# R7KA8M2AD register map
Vendor: Renesas Electronics Corporation; Series: RA8; File version: 1.10.02
CPU: CM85 r0p2, little endian, MPU, FPU, VTOR, 4 interrupt priority bits, 96 interrupts
Registers are 32-bit, read-write, reset 0x0 unless marked. A register's access mark holds for its fields unless they carry their own. Offsets are from the block's base; [hi:lo] are bit positions; {n}, {i} and the like mark numbered series; 'fields as' and 'values as' point back to an identical list.

## MFWD (part 2 of 2) — Forwarding engine
Base 0x403C0000
Same registers: MFWD_NS 0x503C0000
{0x40A0+4i} FWLTHTL{i} (i=1..4) — L3 Table Learn Register {i}
  [31:0] LTHSLP{i} — L3 Stream Learn Part {i}
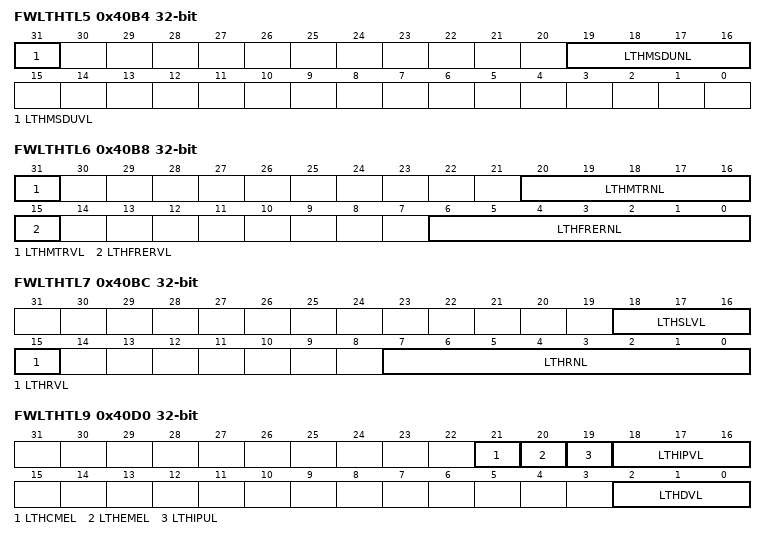
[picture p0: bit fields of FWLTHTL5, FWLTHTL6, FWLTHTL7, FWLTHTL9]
0x40B4 FWLTHTL5 — L3 Table Learn Register 5
  [31] LTHMSDUVL — L3 MSDU Valid Learn
  [19:16] LTHMSDUNL — L3 MSDU Number Learn
0x40B8 FWLTHTL6 — L3 Table Learn Register 6
  [31] LTHMTRVL — L3 Meter Valid Learn
  [20:16] LTHMTRNL — L3 Meter Number Learn
  [15] LTHFRERVL — L3 FRER Valid Learn
  [6:0] LTHFRERNL — L3 FRER Number Learn
0x40BC FWLTHTL7 — L3 Table Learn Register 7
  [18:16] LTHSLVL — L3 Source Lock Vector Learn
  [15] LTHRVL — L3 Routing Valid Learn
  [7:0] LTHRNL — L3 Routing Number Learn
0x40C0 FWLTHTL80 — L3 Table Learn Register 80
  [5:0] LTHCSDL — L3 CPU Sub-Destination Learn
0x40D0 FWLTHTL9 — L3 Table Learn Register 9
  [21] LTHCMEL — L3 CPU Mirroring Enable Learn
  [20] LTHEMEL — L3 Ethernet Mirroring Enable Learn
  [19] LTHIPUL — L3 Internal Priority Update Learn
  [18:16] LTHIPVL — L3 Internal Priority Value Learn
  [2:0] LTHDVL — L3 Destination Vector Learn
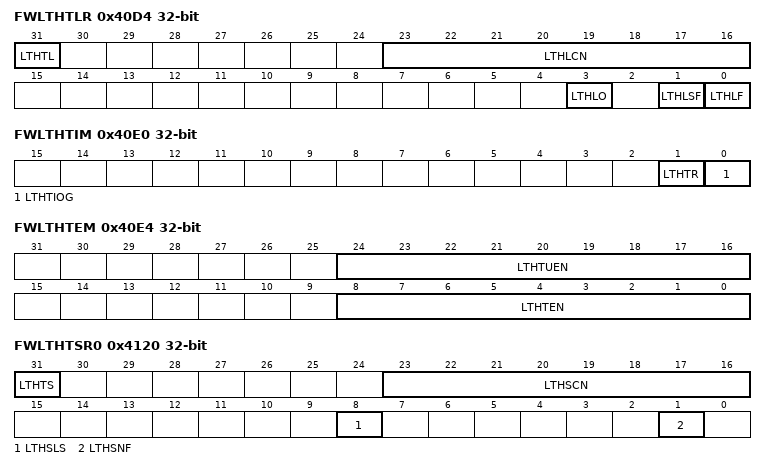
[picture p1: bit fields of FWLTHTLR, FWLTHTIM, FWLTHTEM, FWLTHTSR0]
0x40D4 FWLTHTLR ro — L3 Table Learn Result Register
  [31] LTHTL — L3 Table Learn
  [23:16] LTHLCN — L3 Learn Collision Number
  [3] LTHLO — L3 Learn Overwrite
    0=The entry learning did not overwrite an existing entry; 1=The entry learning overwrote an existing entry
  [1] LTHLSF — L3 Learn Security Fail
    0=Entry learning did not fail. (See .); 1=Entry learning failed. (See .)
  [0] LTHLF — L3 Learn Fail
    values as LTHLSF
0x40E0 FWLTHTIM — L3 Table Initialization Monitoring Register
  [1] LTHTR ro — L3 Table Ready
  [0] LTHTIOG — L3 Table Initialization Ongoing
0x40E4 FWLTHTEM ro — L3 Table Entry Monitoring Register
  [24:16] LTHTUEN — L3 Table Unsecure Entry Number
  [8:0] LTHTEN — L3 Table Entry Number
0x4100 FWLTHTS0 — L3 Table Search Register 0
  [2:0] LTHSSP0 — L3 Stream Search Part 0
{0x4100+4i} FWLTHTS{i} (i=1..4) — L3 Table Search Register {i}
  [31:0] LTHSSP{i} — L3 Stream Search Part {i}
0x4120 FWLTHTSR0 — L3 Table Search Result Register 0
  [31] LTHTS ro — L3 Table Search
  [23:16] LTHSCN ro — L3 Search Collision Number
  [8] LTHSLS ro — L3 Security Level Search
  [1] LTHSNF ro — L3 Search Not found
    0=Stream ID found in L3 Table; 1=Stream ID not found in L3 Table
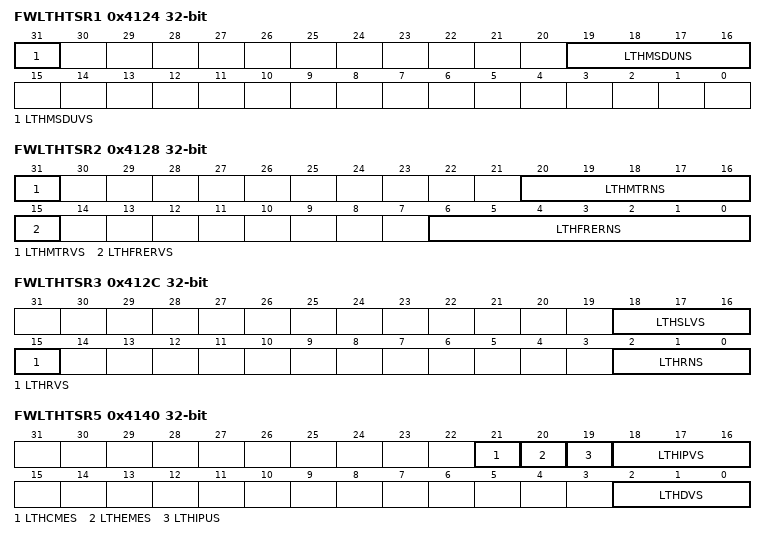
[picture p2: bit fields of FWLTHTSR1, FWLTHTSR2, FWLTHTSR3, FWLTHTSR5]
0x4124 FWLTHTSR1 ro — L3 Table Search Result Register 1
  [31] LTHMSDUVS — L3 MSDU Valid Search
  [19:16] LTHMSDUNS — L3 MSDU Number Search
0x4128 FWLTHTSR2 ro — L3 Table Search Result Register 2
  [31] LTHMTRVS — L3 Meter Valid Search
  [20:16] LTHMTRNS — L3 Meter Number Search
  [15] LTHFRERVS — L3 FRER Valid Search
  [6:0] LTHFRERNS — L3 FRER Number Search
0x412C FWLTHTSR3 ro — L3 Table Search Result Register 3
  [18:16] LTHSLVS — L3 Source Lock Vector Search
  [15] LTHRVS — L3 Routing Valid Search
  [2:0] LTHRNS — L3 Routing Number Search
0x4130 FWLTHTSR40 ro — L3 Table Search Result Register 40
  [5:0] LTHCSDS — L3 CPU Sub-Destination Search
0x4140 FWLTHTSR5 ro — L3 Table Search Result Register 5
  [21] LTHCMES — L3 CPU Mirroring Enable Search
  [20] LTHEMES — L3 Ethernet Mirroring Enable Search
  [19] LTHIPUS — L3 Internal Priority Update Search
  [18:16] LTHIPVS — L3 Internal Priority Value Search
  [2:0] LTHDVS — L3 Destination Vector Search
0x4150 FWLTHTR — L3 Table Read Register
  [7:0] LTHAR — L3 Address Read
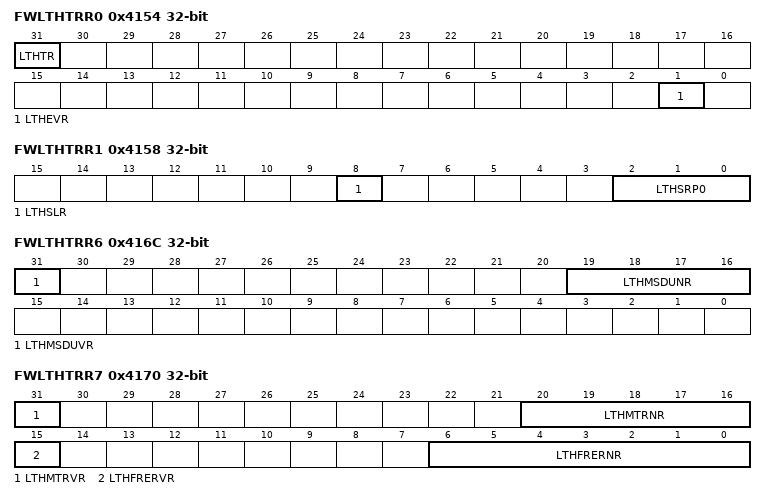
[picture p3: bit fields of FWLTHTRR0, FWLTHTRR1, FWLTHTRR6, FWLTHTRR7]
0x4154 FWLTHTRR0 ro — L3 Table Read Result Register 0
  [31] LTHTR — L3 Table Read
  [1] LTHEVR — L3 Entry Valid Read
0x4158 FWLTHTRR1 ro — L3 Table Read Result Register 1
  [8] LTHSLR — L3 Security Level Read
  [2:0] LTHSRP0 — L3 Stream Read Part 0
{0x4154+4i} FWLTHTRR{i} ro (i=2..5) — L3 Table Read Result Register {i}
  [31:0] LTHSRP{i-1} — L3 Stream Read Part {i-1}
0x416C FWLTHTRR6 ro — L3 Table Read Result Register 6
  [31] LTHMSDUVR — L3 MSDU Valid Read
  [19:16] LTHMSDUNR — L3 MSDU Number Read
0x4170 FWLTHTRR7 ro — L3 Table Read Result Register 7
  [31] LTHMTRVR — L3 Meter Valid Read
  [20:16] LTHMTRNR — L3 Meter Number Read
  [15] LTHFRERVR — L3 FRER Valid Read
  [6:0] LTHFRERNR — L3 FRER Number Read
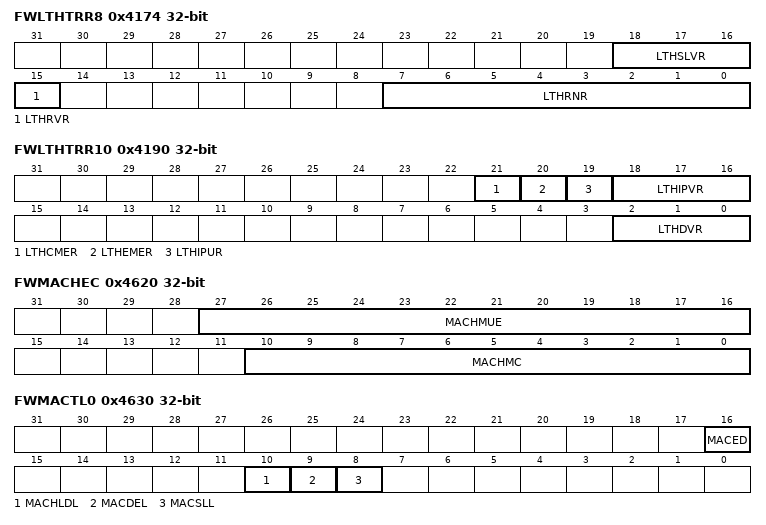
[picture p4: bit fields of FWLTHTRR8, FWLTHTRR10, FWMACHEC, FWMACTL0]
0x4174 FWLTHTRR8 ro — L3 Table Read Result Register 8
  [18:16] LTHSLVR — L3 Source Lock Vector Read
  [15] LTHRVR — L3 Routing Valid Read
  [7:0] LTHRNR — L3 Routing Number Read
0x4180 FWLTHTRR90 ro — L3 Table Read Result Register 90
  [5:0] LTHCSDR — L3 CPU Sub-Destination Read
0x4190 FWLTHTRR10 ro — L3 Table Read Result Register 10
  [21] LTHCMER — L3 CPU Mirroring Enable Read
  [20] LTHEMER — L3 Ethernet Mirroring Enable Read
  [19] LTHIPUR — L3 Internal Priority Update Read
  [18:16] LTHIPVR — L3 Internal Priority Value Read
  [2:0] LTHDVR — L3 Destination Vector Read
0x4620 FWMACHEC — MAC Hash Entry Configuration Register
  [27:16] MACHMUE — MAC Hash Maximum Unsecure Entry
  [10:0] MACHMC — MAC Hash Maximum Collision
0x4624 FWMACHC reset 0x7FF — MAC Hash Configuration Register
  [10:0] MACHE10 to MACHE0 — MAC Hash Equation n (n = 0 to 10)
0x4630 FWMACTL0 — MAC Table Learn Register 0
  [16] MACED — MAC Entry Delete
    0=Learn/overwrite the set MAC address in MAC table; 1=Delete the set MAC address in MAC table
  [10] MACHLDL — MAC Hardware Learning Disable Learn
  [9] MACDEL — MAC Dynamic Entry Learn
  [8] MACSLL — MAC Security Level Learn
0x4634 FWMACTL1 — MAC Table Learn Register 1
  [15:0] MACMALP0 — MAC MAC address Learn Part 0
0x4638 FWMACTL2 — MAC Table Learn Register 2
  [31:0] MACMALP1 — MAC MAC address Learn Part 1
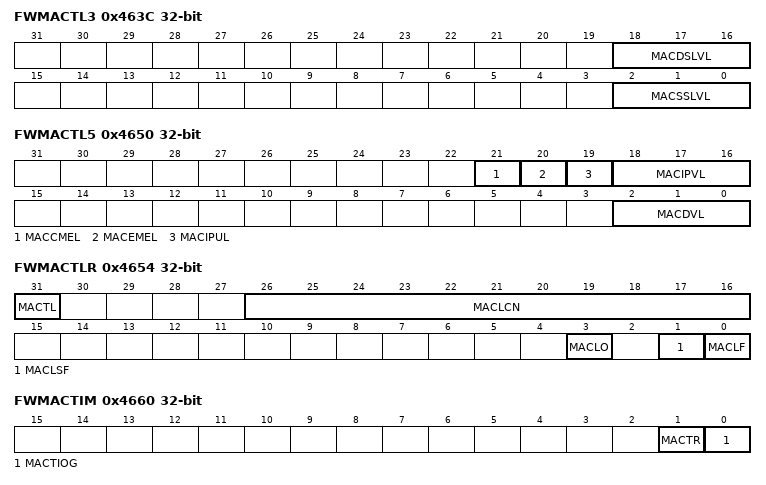
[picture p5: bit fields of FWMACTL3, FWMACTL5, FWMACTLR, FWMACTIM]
0x463C FWMACTL3 — MAC Table Learn Register 3
  [18:16] MACDSLVL — MAC Destination Source Lock Vector Learn
  [2:0] MACSSLVL — MAC Source Source Lock Vector Learn
0x4640 FWMACTL40 — MAC Table Learn Register 40
  [5:0] MACCSDL — MAC CPU Sub-Destination Learn
0x4650 FWMACTL5 — MAC Table Learn Register 5
  [21] MACCMEL — MAC CPU Mirroring Enable Learn
  [20] MACEMEL — MAC Ethernet Mirroring Enable Learn
  [19] MACIPUL — MAC Internal Priority Update Learn
  [18:16] MACIPVL — MAC Internal Priority Value Learn
  [2:0] MACDVL — MAC Destination Vector Learn
0x4654 FWMACTLR ro — MAC Table Learn Result Register
  [31] MACTL — MAC Table Learn
  [26:16] MACLCN — MAC Learn Collision Number
  [3] MACLO — MAC Learn Overwrite
    values as FWLTHTLR.LTHLO
  [1] MACLSF — MAC Learn Security Fail
    0=Entry learning did not fail because of a security error. (See ).; 1=Entry learning failed because of a security error. (See ).
  [0] MACLF — MAC Learn Fail
    0=Entry learning did not fail. (See ).; 1=Entry learning failed. (See ).
0x4660 FWMACTIM — MAC Table Initialization Monitoring Register
  [1] MACTR ro — MAC Table Ready
  [0] MACTIOG — MAC Table Initialization Ongoing
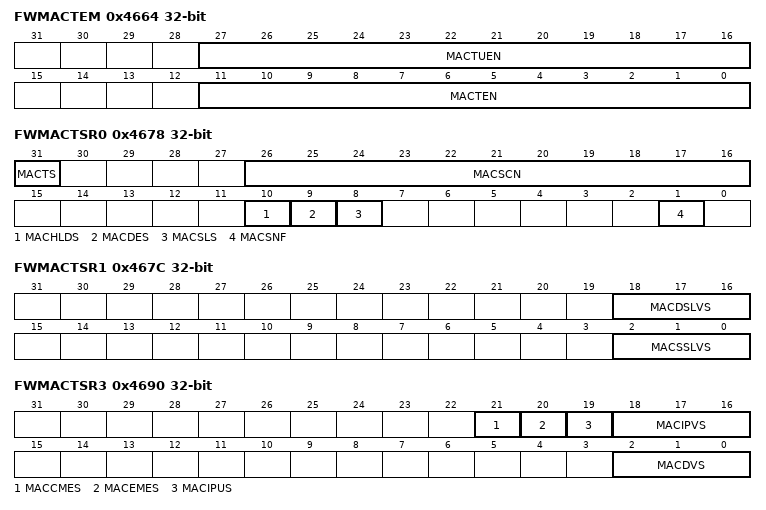
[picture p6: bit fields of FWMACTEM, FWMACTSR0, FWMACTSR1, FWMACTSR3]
0x4664 FWMACTEM ro — MAC Table Entry Monitoring Register
  [27:16] MACTUEN — MAC Table Unsecure Entry Number
  [11:0] MACTEN — MAC Table Entry Number
0x4670 FWMACTS0 — MAC Table Search Register 0
  [15:0] MACMASP0 — MAC MAC Address Search Part 0
0x4674 FWMACTS1 — MAC Table Search Register 1
  [31:0] MACMASP1 — MAC MAC Address Search Part 1
0x4678 FWMACTSR0 — MAC Table Search Result Register 0
  [31] MACTS ro — MAC Table Search
  [26:16] MACSCN ro — MAC Search Collision Number
  [10] MACHLDS ro — MAC Hardware Learning Disable Search
  [9] MACDES ro — MAC Dynamic Entry Search
  [8] MACSLS ro — MAC Security Level Search
  [1] MACSNF ro — MAC Search Not found
    0=MAC address found in MAC Table; 1=MAC address not found in MAC Table
0x467C FWMACTSR1 ro — MAC Table Search Result Register 1
  [18:16] MACDSLVS — MAC Destination Source Lock Vector Search
  [2:0] MACSSLVS — MAC Source Source Lock Vector Search
0x4680 FWMACTSR20 ro — MAC Table Search Result Register 20
  [5:0] MACCSDS — MAC CPU Sub-Destination Search
0x4690 FWMACTSR3 ro — MAC Table Search Result Register 3
  [21] MACCMES — MAC CPU Mirroring Enable Search
  [20] MACEMES — MAC Ethernet Mirroring Enable Search
  [19] MACIPUS — MAC Internal Priority Update Search
  [18:16] MACIPVS — MAC Internal Priority Value Search
  [2:0] MACDVS — MAC Destination Vector Search
0x46A0 FWMACTR — MAC Table Read Register
  [10:0] MACAR — MAC Address Read
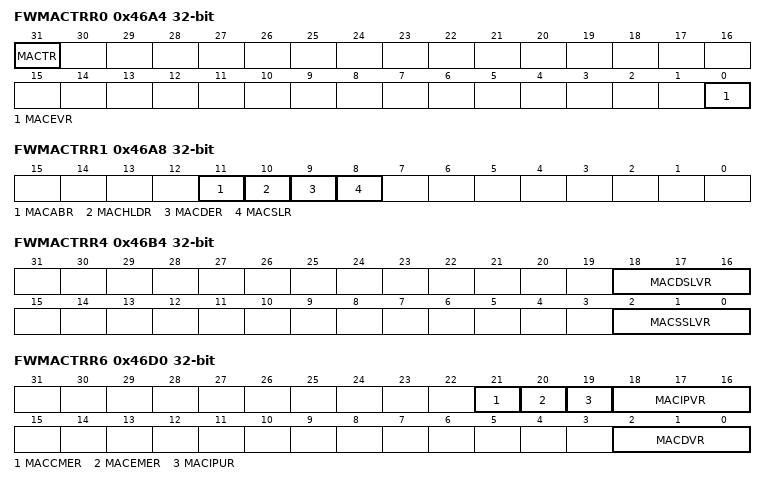
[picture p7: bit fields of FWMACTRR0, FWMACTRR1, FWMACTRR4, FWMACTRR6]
0x46A4 FWMACTRR0 ro — MAC Table Read Result Register 0
  [31] MACTR — MAC Table Read
  [0] MACEVR — MAC Entry Valid Read
0x46A8 FWMACTRR1 ro — MAC Table Read Result Register 1
  [11] MACABR — MAC Aging Bit Read
  [10] MACHLDR — MAC Hardware Learn Disable Read
  [9] MACDER — MAC Dynamic Entry Read
  [8] MACSLR — MAC Security Level Read
0x46AC FWMACTRR2 ro — MAC Table Read Result Register 2
  [15:0] MACMARP0 — MAC MAC address Read Part 0
0x46B0 FWMACTRR3 ro — MAC Table Read Result Register 3
  [31:0] MACMARP1 — MAC MAC Address Read Part 1
0x46B4 FWMACTRR4 ro — MAC Table Read Result Register 4
  [18:16] MACDSLVR — MAC Destination Source Lock Vector Read
  [2:0] MACSSLVR — MAC Source Source Lock Vector Read
0x46C0 FWMACTRR50 ro — MAC Table Read Result Register 50
  [5:0] MACCSDR — MAC CPU Sub-Destination Read
0x46D0 FWMACTRR6 ro — MAC Table Read Result Register 6
  [21] MACCMER — MAC CPU Mirroring Enable Read
  [20] MACEMER — MAC Ethernet Mirroring Enable Read
  [19] MACIPUR — MAC Internal Priority Update Read
  [18:16] MACIPVR — MAC Internal Priority Value Read
  [2:0] MACDVR — MAC Destination Vector Read
0x4880 FWMACAGUSPC — MAC Aging US Prescaler Configuration Register
  [9:0] MACAGUSP — MAC Aging US prescaler
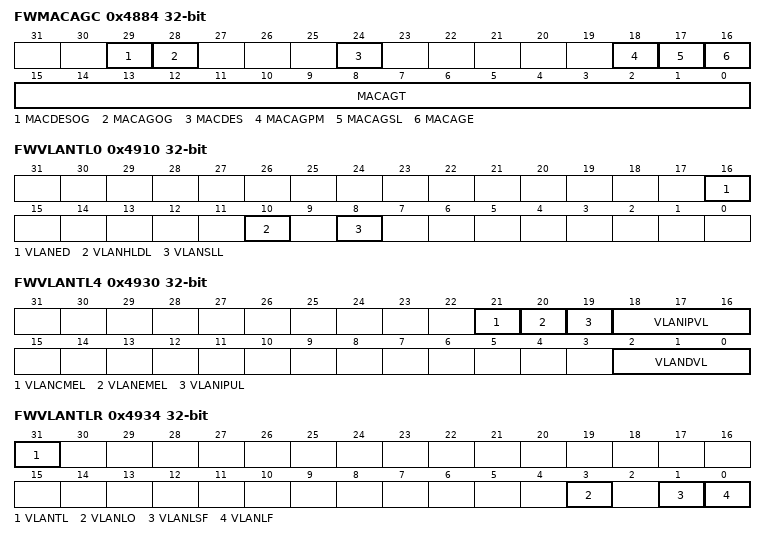
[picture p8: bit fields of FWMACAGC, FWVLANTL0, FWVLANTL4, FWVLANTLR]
0x4884 FWMACAGC — MAC Aging Configuration Register
  [29] MACDESOG ro — MAC Dynamic Entry Suppression Ongoing
    0=MAC Dynamic Entry Suppression is not ongoing; 1=MAC Dynamic Entry Suppression is ongoing
  [28] MACAGOG ro — MAC Aging Ongoing
    0=MAC aging is not ongoing; 1=MAC aging is ongoing
  [24] MACDES ro — MAC Dynamic Entry Suppression
  [18] MACAGPM — MAC Aging Polling Mode
    0=MAC aging polling mode disabled; 1=MAC aging polling mode enabled
  [17] MACAGSL — MAC Aging Security Level
    0=Only unsecure entries will be aged (MAC.SL == 0); 1=All entries will be aged
  [16] MACAGE — MAC Aging Enable
    0=MAC aging is disabled; 1=MAC aging is enabled and will happen every FWMACAGC.MACAGT seconds
  [15:0] MACAGT — MAC Aging Time
0x4888 FWMACAGM0 ro — MAC Aging Monitoring Register 0
  [15:0] AGMACAP0 — Aged MAC Address Part 0
0x488C FWMACAGM1 ro — MAC Aging Monitoring Register 1
  [31:0] AGMACAP1 — Aged MAC Address Part 1
0x4900 FWVLANTEC — VLAN Table Entry Configuration Register
  [28:16] VLANTMUE — VLAN Table Maximum Unsecure Entry
0x4910 FWVLANTL0 — VLAN Table Learn Register 0
  [16] VLANED — VLAN Entry Delete
    0=Learn/overwrite the set VLAN address in VLAN table; 1=Delete the set VLAN address in VLAN table
  [10] VLANHLDL — VLAN Hardware Learning Disable Learn
  [8] VLANSLL — VLAN Security Level Learn
0x4914 FWVLANTL1 — VLAN Table Learn Register 1
  [11:0] VLANVIDL — VLAN VID Learn
0x4918 FWVLANTL2 — VLAN Table Learn Register 2
  [2:0] VLANSLVL — VLAN Source Lock Vector Learn
0x4920 FWVLANTL30 — VLAN Table Learn Register 30
  [5:0] VLANCSDL — VLAN CPU Sub-Destination Learn
0x4930 FWVLANTL4 — VLAN Table Learn Register 4
  [21] VLANCMEL — VLAN CPU Mirroring Enable Learn
  [20] VLANEMEL — VLAN Ethernet Mirroring Enable Learn
  [19] VLANIPUL — VLAN Internal Priority Update Learn
  [18:16] VLANIPVL — VLAN Internal Priority Value Learn
  [2:0] VLANDVL — VLAN Destination Vector Learn
0x4934 FWVLANTLR ro — VLAN Table Learn Result Register
  [31] VLANTL — VLAN Table Learn
  [3] VLANLO — VLAN Learn Overwrite
    values as FWLTHTLR.LTHLO
  [1] VLANLSF — VLAN Learn Security Fail
    0=Entry learning did not fail because of a security error. (See .); 1=Entry learning failed because of a security error. (See .)
  [0] VLANLF — VLAN Learn Fail
    values as FWLTHTLR.LTHLSF
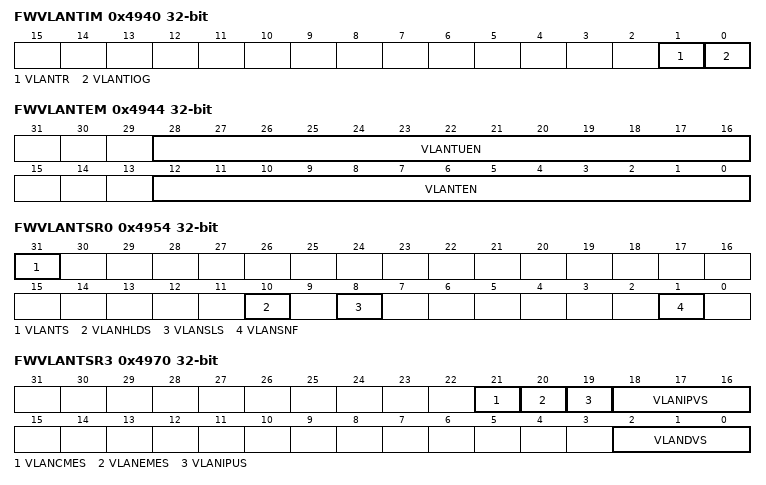
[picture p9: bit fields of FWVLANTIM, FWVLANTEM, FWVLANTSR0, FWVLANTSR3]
0x4940 FWVLANTIM — VLAN Table Initialization Monitoring Register
  [1] VLANTR ro — VLAN Table Ready
  [0] VLANTIOG — VLAN Table Initialization Ongoing
0x4944 FWVLANTEM ro — VLAN Table Entry Monitoring Register
  [28:16] VLANTUEN — VLAN Table Unsecure Entry Number
  [12:0] VLANTEN — VLAN Table Entry Number
0x4950 FWVLANTS — VLAN Table Search Register
  [11:0] VLANVIDS — VLAN VID Search
0x4954 FWVLANTSR0 ro — VLAN Table Search Result Register 0
  [31] VLANTS — VLAN Table Search
  [10] VLANHLDS — VLAN Hardware Learning Disable Search
  [8] VLANSLS — VLAN Security Level Search
  [1] VLANSNF — VLAN Search Not found
    0=VLAN found in VLAN Table; 1=VLAN not found in VLAN Table
0x4958 FWVLANTSR1 ro — VLAN Table Search Result Register 1
  [2:0] VLANSLVS — VLAN Source Lock Vector Search
0x4960 FWVLANTSR20 ro — VLAN Table Search Result Register 20
  [5:0] VLANCSDS — VLAN CPU Sub-Destination Search
0x4970 FWVLANTSR3 ro — VLAN Table Search Result Register 3
  [21] VLANCMES — VLAN CPU Mirroring Enable Search
  [20] VLANEMES — VLAN Ethernet Mirroring Enable Search
  [19] VLANIPUS — VLAN Internal Priority Update Search
  [18:16] VLANIPVS — VLAN Internal Priority Value Search
  [2:0] VLANDVS — VLAN Destination Vector Search
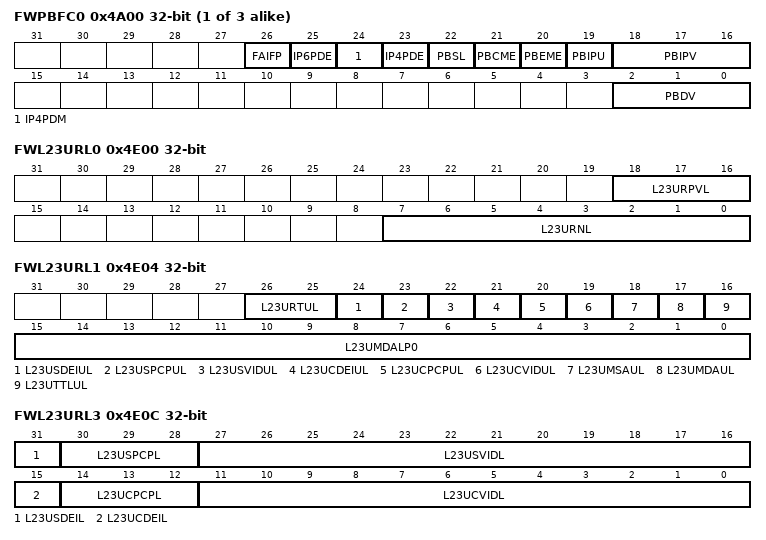
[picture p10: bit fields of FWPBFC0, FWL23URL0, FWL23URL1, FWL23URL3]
{0x4A00+0x10*i} FWPBFC{i} (i=0..2) — Port {i} Port Based Forwarding Configuration Register
  [26] FAIFP — Force All Input Frame Priority Enable
    0=For port i, Input frame priority is given by frame decoding; 1=For port i, Input frame priority is forced to FWPBFCi.PBIPV
  [25] IP6PDE — IPv6 Priority Decode Enable
    0=For port i, Input frame priority is taken from VLAN TAGs; 1=For port i, If an IPv6 frame is detected, input frame priority is decoded from DSCP field in ToS. Else Input frame priority is taken from VLAN TAGs.
  [24] IP4PDM — IPv4 Priority Decode Mode
    0=For port i, Input frame priority is taken from precedent field in ToS; 1=For port i, Input frame priority is decoded from DSCP field in ToS
  [23] IP4PDE — IPv4 Priority Decode Enable
    0=For port i, Input frame priority is taken from VLAN TAGs for port i; 1=For port i, If an IPv4 frame is detected, input frame priority is taken from precedence ToS. Else Input frame priority is taken from VLAN TAGs.
  [22] PBSL — Port Based Security Level
  [21] PBCME — Port Based CPU Mirroring Enabled
  [20] PBEME — Port Based Ethernet Mirroring Enabled
  [19] PBIPU — Port Based Internal Priority Update
  [18:16] PBIPV — Port Based Internal Priority Value
  [2:0] PBDV — Port Based Destination Vector
{0x4A04+0x10*i} FWPBFCSDC{i}0 (i=0..2) — Port {i} Port Based Forwarding CSD Configuration Register 0
  [5:0] PBCSD — Port Based CPU Sub Destination
0x4E00 FWL23URL0 — Layer 2/Layer 3 Update Rule Learn Register 0
  [18:16] L23URPVL — Layer 2/Layer 3 Update Routing Port Valid Learn
  [7:0] L23URNL — Layer 2/Layer 3 Update Routing Number Learn
0x4E04 FWL23URL1 — Layer 2/Layer 3 Update Rule Learn Register 1
  [26:25] L23URTUL — Layer 2/Layer 3 Update R-TAG Update Learn
  [24] L23USDEIUL — Layer 2/Layer 3 Update S-TAG DEI Update Learn
  [23] L23USPCPUL — Layer 2/Layer 3 Update S-TAG PCP Update Learn
  [22] L23USVIDUL — Layer 2/Layer 3 Update S-TAG VID Update Learn
  [21] L23UCDEIUL — Layer 2/Layer 3 Update C-TAG DEI Update Learn
  [20] L23UCPCPUL — Layer 2/Layer 3 Update C-TAG PCP Update Learn
  [19] L23UCVIDUL — Layer 2/Layer 3 Update C-TAG VID Update Learn
  [18] L23UMSAUL — Layer 2/Layer 3 Update MAC Source Address Update Learn
  [17] L23UMDAUL — Layer 2/Layer 3 Update MAC Destination Address Update Learn
  [16] L23UTTLUL — Layer 2/Layer 3 Update Time To Live Update Learn
  [15:0] L23UMDALP0 — Layer 2/Layer 3 Update MAC Destination Address Learn Part 0
0x4E08 FWL23URL2 — Layer 2/Layer 3 Update Rule Learn Register 2
  [31:0] L23UMDALP1 — Layer 2/Layer 3 Update MAC Destination Address Learn Part 1
0x4E0C FWL23URL3 — Layer 2/Layer 3 Update Rule Learn Register 3
  [31] L23USDEIL — Layer 2/Layer 3 Update S-TAG DEI Learn
  [30:28] L23USPCPL — Layer 2/Layer 3 Update S-TAG PCP Learn
  [27:16] L23USVIDL — Layer 2/Layer 3 Update S-TAG VID Learn
  [15] L23UCDEIL — Layer 2/Layer 3 Update C-TAG DEI Learn
  [14:12] L23UCPCPL — Layer 2/Layer 3 Update C-TAG PCP Learn
  [11:0] L23UCVIDL — Layer 2/Layer 3 Update C-TAG VID Learn
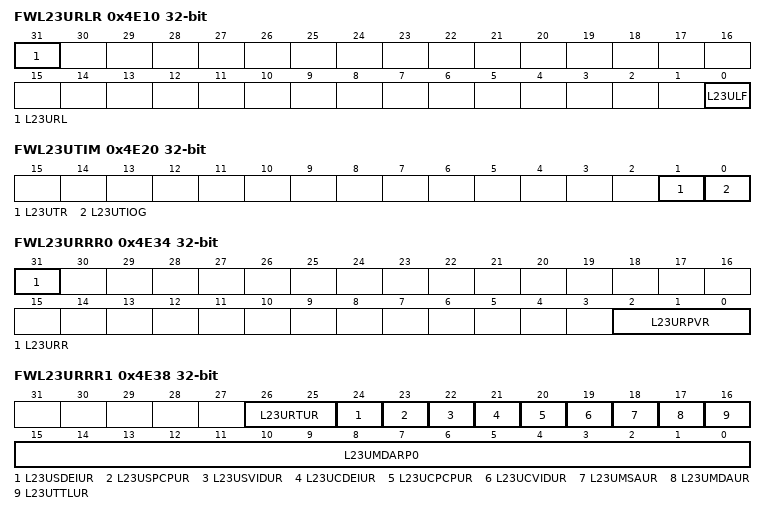
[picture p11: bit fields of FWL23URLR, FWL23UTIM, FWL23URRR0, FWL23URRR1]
0x4E10 FWL23URLR ro — Layer 2/Layer 3 Update Rule Learn Result Register
  [31] L23URL — Layer 2/Layer 3 Update Rule Learn
  [0] L23ULF — Layer 2/Layer 3 Update Learn Fail
    0=Entry learning did not fail because the Layer 2/Layer 3 table is ready; 1=Entry learning failed because the Layer 2/Layer 3 table is not ready
0x4E20 FWL23UTIM — Layer 2/Layer 3 Update Table Initialization Monitoring Register
  [1] L23UTR ro — Layer 2/Layer 3 Update Table Ready
  [0] L23UTIOG — Layer 2/Layer 3 Update Table Initialization Ongoing
0x4E30 FWL23URR — Layer 2/Layer 3 Update Rule Read Register
  [7:0] L23RNR — Layer 2/Layer 3 Routing Number Read
0x4E34 FWL23URRR0 ro — Layer 2/Layer 3 Update Rule Read Result Register 0
  [31] L23URR — Layer 2/Layer 3 Update Rule Read
  [2:0] L23URPVR — Layer 2/Layer 3 Update Routing Port Valid Read
0x4E38 FWL23URRR1 ro — Layer 2/Layer 3 Update Rule Read Result Register 1
  [26:25] L23URTUR — Layer 2/Layer 3 R-TAG Update Read
  [24] L23USDEIUR — Layer 2/Layer 3 S-TAG DEI Update Read
  [23] L23USPCPUR — Layer 2/Layer 3 S-TAG PCP Update Read
  [22] L23USVIDUR — Layer 2/Layer 3 S-TAG VID Update Read
  [21] L23UCDEIUR — Layer 2/Layer 3 C-TAG DEI Update Read
  [20] L23UCPCPUR — Layer 2/Layer 3 C-TAG PCP Update Read
  [19] L23UCVIDUR — Layer 2/Layer 3 C-TAG VID Update Read
  [18] L23UMSAUR — Layer 2/Layer 3 MAC Source Address Update Read
  [17] L23UMDAUR — Layer 2/Layer 3 MAC Destination Address Update Read
  [16] L23UTTLUR — Layer 2/Layer 3 Time To Live Update Read
  [15:0] L23UMDARP0 — Layer 2/Layer 3 MAC Destination Address Read Part 0
0x4E3C FWL23URRR2 ro — Layer 2/Layer 3 Update Rule Read Result Register 2
  [31:0] L23UMDARP1 — Layer 2/Layer 3 Update MAC Destination Address Read Part 1
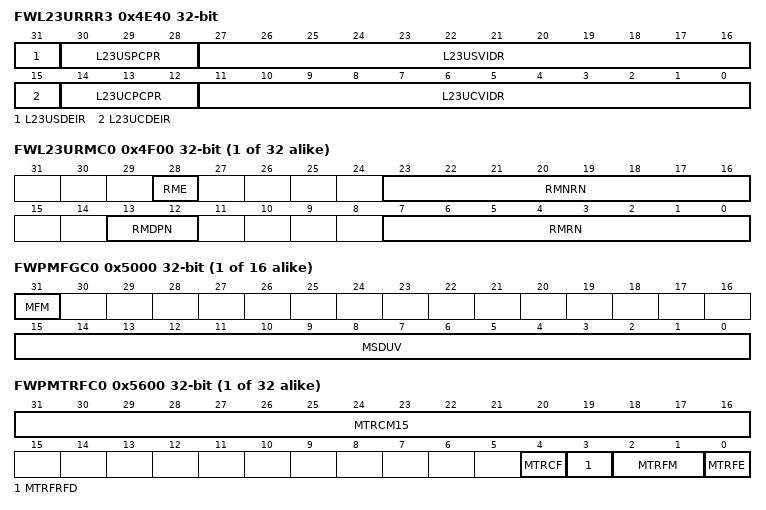
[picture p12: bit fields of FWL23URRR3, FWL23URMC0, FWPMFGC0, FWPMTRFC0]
0x4E40 FWL23URRR3 ro — Layer 2/Layer 3 Update Rule Read Result Register 3
  [31] L23USDEIR — Layer 2/Layer 3 Update MAC S-TAG DEI Read
  [30:28] L23USPCPR — Layer 2/Layer 3 Update MAC S-TAG PCP Read
  [27:16] L23USVIDR — Layer 2/Layer 3 Update MAC S-TAG VID Read
  [15] L23UCDEIR — Layer 2/Layer 3 Update MAC C-TAG DEI Read
  [14:12] L23UCPCPR — Layer 2/Layer 3 Update MAC C-TAG PCP Read
  [11:0] L23UCVIDR — Layer 2/Layer 3 Update MAC C-TAG VID Read
{0x4F00+4i} FWL23URMC{i} (i=0..31) — Layer 2/Layer 3 Update Remapping Configuration Register {i}
  [28] RME — Remapping Enable
    0=Remapping rule i disabled; 1=Remapping rule i enabled
  [23:16] RMNRN — Remapping New Rule Number
  [13:12] RMDPN — Remapping Destination Port Number
  [7:0] RMRN — Remapping Rule Number
{0x5000+4i} FWPMFGC{i} (i=0..15) — PSFP MSDU Filter Global Configuration Register {i}
  [31] MFM — MSDU Filter Mode
    0=Normal mode: Any frame linked to MSDU filter i thanks to L3 table received with LDESCR.TPL [GWCA] bigger than FWPMPCi.MSDUV will be filtered; 1=Throttle mode: Any frame linked to MSDU filter i thanks to L3 table received with LDESCR.TPL [GWCA] bigger than FWPMPCi.MSDUV will be filtered. Any frame linked to MSDU filter i thanks to L3 table received when FWEIS2.PMFSi is set will be filtered.
  [15:0] MSDUV — MSDU Value
{0x5600+0x20*i} FWPMTRFC{i} (i=0..31) — PSFP Meter {i} Filter Configuration Register
  [31:16] MTRCM15 to MTRCM0 — Meter Color Mode n (n = 0 to 15)
  [4] MTRCF — Meter Coupling Flag
    0=When green bucket is full, CIR tokens are lost; 1=When green bucket is full, CIR tokens are added to the yellow bucket
  [3] MTRFRFD — Meter Filter Red Frame Drop
    0=Red frames are not dropped by meter i; 1=Red frames are dropped by meter i
  [2:1] MTRFM — Meter Filter Mode
    0=Normal mode: Any frame linked to Meter filter i thanks to L3 table received when not enough token is available will be red; 1=Throttle mode: Any frame linked to Meter filter i thanks to L3 table received when not enough token is available or when FWEIS5.PMRFSi is set will be red; 2=ATS mode: Any frame linked to Meter filter i thanks to L3 table received when not enough token is available will be stored in ATS RAM until enough tokens are available. When enough tokens are available, frame will be forwarded as yellow or green.; 3=ATS throttle mode: Any frame linked to Meter filter i thanks to L3 table received when not enough token is available will be stored in ATS RAM until enough tokens are available. When enough tokens are available, frame will be forwarded as yellow or green if FWEIS5.PMRFSi is not set and will be red if FWEIS5.PMRFSi is set.
  [0] MTRFE — Meter Filter Enable
    0=Meter i disabled (Pass through all frames.); 1=Meter i enabled (Reject target stream frames by meter filter.)
{0x5604+0x20*i} FWPMTRCBSC{i} (i=0..31) — PSFP Meter {i} CBS Configuration Register
  [17:0] CBS
{0x5608+0x20*i} FWPMTRCIRC{i} (i=0..31) — PSFP Meter {i} CIR Configuration Register
  [19:0] CIR
{0x560C+0x20*i} FWPMTREBSC{i} (i=0..7) — PSFP Meter {i} EBS Configuration Register
  [17:0] EBS
{0x5610+0x20*i} FWPMTREIRC{i} (i=0..7) — PSFP Meter {i} EIR Configuration Register
  [19:0] EIR
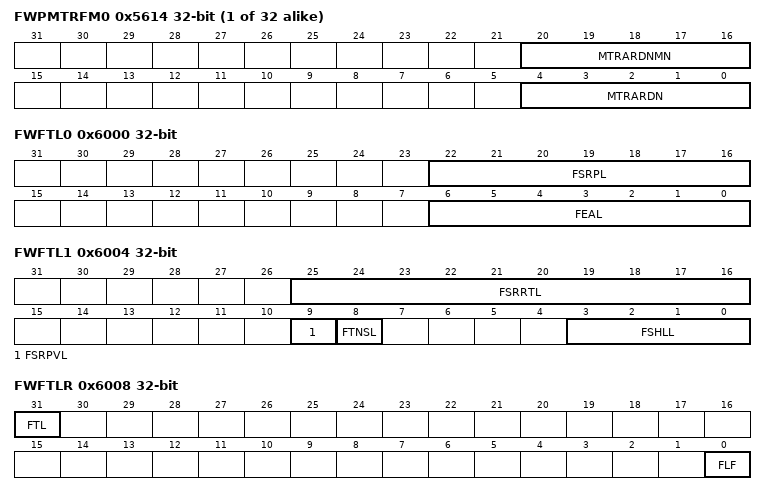
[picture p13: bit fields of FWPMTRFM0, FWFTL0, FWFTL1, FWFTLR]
{0x5614+0x20*i} FWPMTRFM{i} (i=0..31) ro — PSFP Meter {i} Filter Monitoring Register
  [20:16] MTRARDNMN — Meter ATS RAM Descriptor Number Maximum Number
  [4:0] MTRARDN — Meter ATS RAM Descriptor Number
0x6000 FWFTL0 — FRER Table Learn Register 0
  [22:16] FSRPL — FRER Sequence Recovery Pointer Learn
  [6:0] FEAL — FRER Entry Address Learn
0x6004 FWFTL1 — FRER Table Learn Register 1
  [25:16] FSRRTL — FRER Sequence Recovery Remaining Ticks Learn
  [9] FSRPVL — FRER Sequence Recovery Pointer Valid Learn
  [8] FTNSL — FRER Take No Sequence Learn
  [3:0] FSHLL — FRER Sequence History Length Learn
0x6008 FWFTLR ro — FRER Table Learn Result Register
  [31] FTL — FRER Table Learn
  [0] FLF — FRER Learn Fail
    0=Entry learning did not fail because the FRER RAM is ready; 1=Entry learning failed because the FRER RAM is not ready
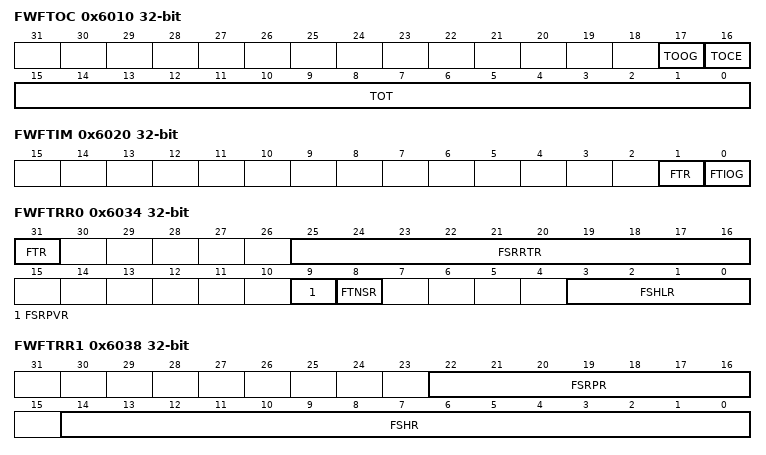
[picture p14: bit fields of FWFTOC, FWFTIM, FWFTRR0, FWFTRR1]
0x6010 FWFTOC — FRER Timeout Configuration Register
  [17] TOOG — Timeout Ongoing
    0=Timeout check is not ongoing; 1=Timeout check is ongoing
  [16] TOCE — Timeout Check Enable
    0=Timeout check is disabled; 1=Timeout check is enabled
  [15:0] TOT — Timeout Time (ms)
0x6014 FWFTOPC — FRER Timeout Prescaler Configuration Register 0
  [9:0] USP — Microsecond Prescaler
0x6020 FWFTIM — FRER Table Initialization Monitoring Register
  [1] FTR ro — FRER Table Ready
  [0] FTIOG — FRER Table Initialization Ongoing
0x6030 FWFTR — FRER Table Read Register
  [6:0] FEAR — FRER Entry Address Read
0x6034 FWFTRR0 ro — FRER Table Read Result Register 0
  [31] FTR — FRER Table Read
  [25:16] FSRRTR — FRER Set Recovery Remaining Ticks Read
  [9] FSRPVR — FRER Sequence Recovery Pointer Valid Read
  [8] FTNSR — FRER Take No Sequence Read
  [3:0] FSHLR — FRER Sequence History Length Read
0x6038 FWFTRR1 ro — FRER Table Read Result Register 1
  [22:16] FSRPR — FRER Sequence Recovery Pointer Read
  [14:0] FSHR — FRER Sequence History Read
0x603C FWFTRR2 ro — FRER Table Read Result Register 2
  [25:16] FRRTR — FRER Recovery Remaining Ticks Read
  [15:0] FRSNR — FRER Recovery Sequence Number Read
{0x6100+8i} FWSEQNGC{i} (i=0..31) — Sequence Number Generation {i} Configuration Register
  [16] SEQNGE — SEQuence Number Generation Enable
    0=Sequence number generation disabled for routing number FWSEQNGCi.SEQNGRN; 1=Sequence number generation enabled for routing number FWSEQNGCi.SEQNGRN
  [7:0] SEQNGRN — SEQuence Number Generation Routing Number
{0x6104+8i} FWSEQNGM{i} (i=0..31) ro — Sequence Number Generation {i} Monitoring Register
  [15:0] SEQN — SEQuence Number
0x6200 FWSEQNRC wo — Sequence Number Reset Configuration Register
  [all] fields
    0=No effect; 1=Bit i of this register reset to 0 the sequence generator number i counter
  [n] SEQNR{n:02} (n=0..31) — Sequence Number Generation Reset n (n = 0 to 31)
{0x6300+0x20*i} FWCTFDCN{i} (i=0..1) ro — Port {i} Cut-Through Forwarded Descriptor Counter Register
  [31:0] CTFDN — Cut-Through Forwarded Descriptor Number
{0x6304+0x20*i} FWLTHFDCN{i} (i=0..2) ro — Port {i} Layer 3 Forwarded Descriptor Counter Register
  [31:0] LTHFDN — Layer 3 Forwarded Descriptor Number
{0x630C+0x20*i} FWLTWFDCN{i} (i=0..2) ro — Port {i} Layer 2 Forwarded Descriptor Counter Register
  [31:0] LTWFDN — Layer 2 Forwarded Descriptor Number
{0x6310+0x20*i} FWPBFDCN{i} (i=0..2) ro — Port {i} Port Based Forwarded Descriptor Counter Register
  [31:0] PBFDN — Port Based Forwarded Descriptor Number
{0x6314+0x20*i} FWMHLCN{i} (i=0..2) ro — Port {i} MAC Hardware Learn Counter Register
  [31:0] MHLN — MAC Hardware Learn Number
0x6340 FWDDFDCN2 ro — Port 2 Direct Descriptor Forwarded Descriptor Counter Register
  [31:0] DDFDN — Direct Descriptor Forwarded Descriptor Number
{0x6504+0x20*i} FWWMRDCN{i} (i=0..2) ro — Port {i} Watermark Rejected Descriptor Counter Register
  [15:0] WMRDN — Watermark rejected Descriptor Number
{0x6508+0x20*i} FWCTRDCN{i} (i=0..1) ro — Port {i} Cut-Through Rejected Descriptor Counter Register
  [15:0] CTRDN — Cut-through rejected Descriptor Number
{0x650C+0x20*i} FWLTHRDCN{i} (i=0..2) ro — Port {i} Layer 3 Rejected Descriptor Counter Register
  [15:0] LTHRDN — Layer 3 rejected Descriptor Number
{0x6514+0x20*i} FWLTWRDCN{i} (i=0..2) ro — Port {i} Layer 2 Rejected Descriptor Counter Register
  [15:0] LTWRDN — Layer 2 rejected Descriptor Number
{0x6518+0x20*i} FWPBRDCN{i} (i=0..2) ro — Port {i} Port Based Rejected Descriptor Counter Register
  [15:0] PBRDN — Port Based rejected Descriptor Number
0x6548 FWDDRDCN2 ro — Port 2 Direct Descriptor Rejected Descriptor Counter Register
  [15:0] DDRDN — Direct Descriptor rejected Descriptor Number
{0x6700+4i} FWPMFDCN{i} (i=0..15) ro — PSFP MSDU {i} Filtered Descriptor Counter Register
  [15:0] PMFDN — PSFP MSDU Filtered Descriptor Number
{0x6800+0x10*i} FWPMGDCN{i} (i=0..31) ro — PSFP Meter {i} Green Descriptor Counter Register
  [15:0] PMGDN — PSFP Meter Green Descriptor Number
{0x6804+0x10*i} FWPMYDCN{i} (i=0..7) ro — PSFP Meter {i} Yellow Descriptor Counter Register
  [15:0] PMYDN — PSFP Meter Yellow Descriptor Number
{0x6808+0x10*i} FWPMRDCN{i} (i=0..31) ro — PSFP Meter {i} Red Descriptor Counter Register
  [15:0] PMRDN — PSFP Meter Red Descriptor Number
{0x6A00+8i} FWFRPPCN{i} (i=0..127) ro — FRER {i} Passed Packet Counter Register
  [15:0] PPC — Passed Packet Count
{0x6A04+8i} FWFRDPCN{i} (i=0..127) ro — FRER {i} Discarded Packet Counter Register
  [15:0] DPC — Discarded Packet Count
{0x7900+0x10*i} FWEIS0{i} (i=0..2) — Port {i} Error Interrupt Status Register 0
  [29] DDNTFS — Direct Descriptor No Target Filtering Status Flag
  [28] DDSES — Direct Descriptor Security Error Status Flag
  [26] DDES — Direct Descriptor Error Status Flag
  [25] WMIUFS — Watermark IPV Unsecure Filtering Status Flag
  [24] WMISFS — Watermark IPV Secure Filtering Status Flag
  [23] WMFFS — Watermark Flush Filtering Status Flag
  [22] WMCFS — Watermark Critical Filtering Status Flag
  [19] SMHMFS — Source MAC Hardware Migration Fail Status Flag
  [18] SMHLFS — Source MAC Hardware Learning Fail Status Flag
  [17] PBNTFS — Port Based No Target Filtering Status Flag
  [16] LTWVUFS — Layer 2 VLAN Unknown Filtering Status Flag
  [15] LTWDUFS — Layer 2 Destination Unknown Filtering Status Flag
  [14] LTWSUFS — Layer 2 Source Unknown Filtering Status Flag
  [13] LTWNTFS — Layer 2 No Target Filtering Status Flag
  [12] LTWVSPFS — Layer 2 VLAN Source Port Filtering Status Flag
  [11] LTWSSPFS — Layer 2 Source Source Port Filtering Status Flag
  [10] LTWDSPFS — Layer 2 Destination Source Port Filtering Status Flag
  [3] LTHUFS — Layer 3 Unknown Filtering Status Flag
  [2] LTHNTFS — Layer 3 No Target Filtering Status Flag
  [0] LTHSPFS — Layer 3 Source Port Filtering Status Flag
{0x7904+0x10*i} FWEIE0{i} (i=0..2) — Port {i} Error Interrupt Enable Register 0
  [all] fields
    0=Interrupt i disabled; 1=Interrupt i Enabled
  [29] DDNTFE — Direct Descriptor No Target Filtering Enable
  [28] DDSEE — Direct Descriptor Security Error Enable
  [27] DDFEE — Direct Descriptor Format Error Enable
  [26] DDEE — Direct Descriptor Error Enable
  [25] WMIUFE — Watermark IPV Unsecure Filtering Enable
  [24] WMISFE — Watermark IPV Secure Filtering Enable
  [23] WMFFE — Watermark Flush Filtering Enable
  [22] WMCFE — Watermark Critical Filtering Enable
  [19] SMHMFE — Source MAC Hardware Migration Fail Enable
  [18] SMHLFE — Source MAC Hardware Learning Fail Enable
  [17] PBNTFE — Port Based No Target Filtering Enable
  [16] LTWVUFE — Layer 2 VLAN Unknown Filtering Enable
  [15] LTWDUFE — Layer 2 Destination Unknown Filtering Enable
  [14] LTWSUFE — Layer 2 Source Unknown Filtering Enable
  [13] LTWNTFE — Layer 2 No Target Filtering Enable
  [12] LTWVSPFE — Layer 2 VLAN Source Port Filtering Enable
  [11] LTWSSPFE — Layer 2 Source Source Port Filtering Enable
  [10] LTWDSPFE — Layer 2 Destination Source Port Filtering Enable
  [3] LTHUFE — Layer 3 Unknown Filtering Enable
  [2] LTHNTFE — Layer 3 No Target Filtering Enable
  [0] LTHSPFE — Layer 3 Source Port Filtering Enable
{0x7908+0x10*i} FWEID0{i} (i=0..2) — Port {i} Error Interrupt Disable Register 0
  [29] DDNTFD — Direct Descriptor No Target Filtering Disable
  [28] DDSED — Direct Descriptor Security Error Disable
  [27] DDFED — Direct Descriptor Format Error Disable
  [26] DDED — Direct Descriptor Error Disable
  [25] WMIUFD — Watermark IPV Unsecure Filtering Disable
  [24] WMISFD — Watermark IPV Secure Filtering Disable
  [23] WMFFD — Watermark Flush Filtering Disable
  [22] WMCFD — Watermark Critical Filtering Disable
  [19] SMHMFD — Source MAC Hardware Migration Fail Disable
  [18] SMHLFD — Source MAC Hardware Learning Fail Disable
  [17] PBNTFD — Port Based No Target Filtering Disable
  [16] LTWVUFD — Layer 2 VLAN Unknown Filtering Disable
  [15] LTWDUFD — Layer 2 Destination Unknown Filtering Disable
  [14] LTWSUFD — Layer 2 Source Unknown Filtering Disable
  [13] LTWNTFD — Layer 2 No Target Filtering Disable
  [12] LTWVSPFD — Layer 2 VLAN Source Port Filtering Disable
  [11] LTWSSPFD — Layer 2 Source Source Port Filtering Disable
  [10] LTWDSPFD — Layer 2 Destination Source Port Filtering Disable
  [3] LTHUFD — Layer 3 Unknown Filtering Disable
  [2] LTHNTFD — Layer 3 No Target Filtering Disable
  [0] LTHSPFD — Layer 3 Source Port Filtering Disable
0x7A00 FWEIS1 — Error Interrupt Status Register 1
  [7] VLANTSES — VLAN Table Security Error Status Flag
  [5] MACTSES — MAC Table Security Error Status Flag
  [1] LTHTSES — L3 Table Security Error Status Flag
0x7A04 FWEIE1 — Error Interrupt Enable Register 1
  [all] fields
    0=Interrupt disabled; 1=Interrupt Enabled
  [7] VLANTSEE — VLAN Table Security Error Enable
  [5] MACTSEE — MAC Table Security Error Enable
  [1] LTHTSEE — L3 Table Security Error Enable
0x7A08 FWEID1 — Error Interrupt Disable Register 1
  [8] L23UEED — Layer 2/Layer 3 Update Error Disable
  [7] VLANTSED — VLAN Table Security Error Disable
  [5] MACTSED — MAC Table Security Error Disable
  [1] LTHTSED — L3 Table Security Error Disable
0x7A10 FWEIS2 — Error Interrupt Status Register 2
  [15:0] PMFS15 to PMFS0 — PSFP MSDU n Filtering Status Flag (n = 0 to 15)
0x7A14 FWEIE2 — Error Interrupt Enable Register 2
  [15:0] PMFE15 to PMFE0 — PSFP MSDU n Filtering Enable (n = 0 to 15)
    0=Interrupt disabled; 1=Interrupt Enabled
0x7A18 FWEID2 — Error Interrupt Disable Register 2
  [15:0] PMFD15 to PMFD0 — PSFP MSDU n Filtering Disable (n = 0 to 15)
0x7A40 FWEIS5 — Error Interrupt Status Register 5
  [31:0] PMRFS31 to PMRFS0 — PSFP Meter n Filtering Status Flag (n = 0 to 31)
0x7A44 FWEIE5 — Error Interrupt Enable Register 5
  [31:0] PMRFE31 to PMRFE0 — PSFP Meter n Filtering Enable (n = 0 to 31)
0x7A48 FWEID5 — Error Interrupt Disable Register 5
  [31:0] PMRFD31 to PMRFD0 — PSFP Meter n Filtering Disable (n = 0 to 31)
0x7A50 FWEIS60 — Error Interrupt Status Register 60
  [31:0] FFS31 to FFS0 — FRER n Filtering Status Flag (n = 96 to 127)
0x7A54 FWEIE60 — Error Interrupt Enable Register 60
  [31:0] FFE31 to FFE0 — FRER n Filtering Enable (n = 96 to 127)
0x7A58 FWEID60 — Error Interrupt Disable Register 60
  [31:0] FFD31 to FFD0 — FRER n Filtering Disable (n = 96 to 127)
0x7A60 FWEIS61 — Error Interrupt Status Register 61
  [31:0] FFS31 to FFS0 — FRER n Filtering Status Flag (n = 64 to 95)
0x7A64 FWEIE61 — Error Interrupt Enable Register 61
  [31:0] FFE31 to FFE0 — FRER n Filtering Enable (n = 64 to 95)
0x7A68 FWEID61 — Error Interrupt Disable Register 61
  [31:0] FFD31 to FFD0 — FRER n Filtering Disable (n = 64 to 95)
0x7A70 FWEIS62 — Error Interrupt Status Register 62
  [31:0] FFS31 to FFS0 — FRER n Filtering Status Flag (n = 32 to 63)
0x7A74 FWEIE62 — Error Interrupt Enable Register 62
  [31:0] FFE31 to FFE0 — FRER n Filtering Enable (n = 32 to 63)
0x7A78 FWEID62 — Error Interrupt Disable Register 62
  [31:0] FFD31 to FFD0 — FRER n Filtering Disable (n = 32 to 63)
0x7A80 FWEIS63 — Error Interrupt Status Register 63
  [31:0] FFS31 to FFS0 — FRER n Filtering Status Flag (n = 0 to 31)
0x7A84 FWEIE63 — Error Interrupt Enable Register 63
  [31:0] FFE31 to FFE0 — FRER n Filtering Enable (n = 0 to 31)
0x7A88 FWEID63 — Error Interrupt Disable Register 63
  [31:0] FFD31 to FFD0 — FRER n Filtering Disable (n = 0 to 31)
0x7A90 FWEIS70 — Error Interrupt Status Register 70
  [31:0] FOORS31 to FOORS0 — FRER n Out Of Range Status Flag (n = 96 to 127)
0x7A94 FWEIE70 — Error Interrupt Enable Register 70
  [31:0] FOORE31 to FOORE0 — FRER n Out Of Range Enable (n = 96 to 127)
0x7A98 FWEID70 — Error Interrupt Disable Register 70
  [31:0] FOORD31 to FOORD0 — FRER n Out Of Range Disable (n = 96 to 127)
0x7AA0 FWEIS71 — Error Interrupt Status Register 71
  [31:0] FOORS31 to FOORS0 — FRER n Out Of Range Status Flag (n = 64 to 95)
0x7AA4 FWEIE71 — Error Interrupt Enable Register 71
  [31:0] FOORE31 to FOORE0 — FRER n Out Of Range Enable (n = 64 to 95)
0x7AA8 FWEID71 — Error Interrupt Disable Register 71
  [31:0] FOORD31 to FOORD0 — FRER n Out Of Range Disable (n = 64 to 95)
0x7AB0 FWEIS72 — Error Interrupt Status Register 72
  [31:0] FOORS31 to FOORS0 — FRER n Out Of Range Status Flag (n = 32 to 63)
0x7AB4 FWEIE72 — Error Interrupt Enable Register 72
  [31:0] FOORE31 to FOORE0 — FRER n Out Of Range Enable (n = 32 to 63)
0x7AB8 FWEID72 — Error Interrupt Disable Register 72
  [31:0] FOORD31 to FOORD0 — FRER n Out Of Range Disable (n = 32 to 63)
0x7AC0 FWEIS73 — Error Interrupt Status Register 73
  [31:0] FOORS31 to FOORS0 — FRER n Out Of Range Status Flag (n = 0 to 31)
0x7AC4 FWEIE73 — Error Interrupt Enable Register 73
  [31:0] FOORE31 to FOORE0 — FRER n Out Of Range Enable (n = 0 to 31)
0x7AC8 FWEID73 — Forwarding Engine Error Interrupt Disable 73
  [31:0] FOORD31 to FOORD0 — FRER n Out Of Range Disable (n = 0 to 31)
0x7AD0 FWEIS80 — Error Interrupt Status Register 80
  [31:0] TOS31 to TOS0 — Timeout Status Flag n (n = 96 to 127)
0x7AD4 FWEIE80 — Error Interrupt Enable Register 80
  [31:0] TOE31 to TOE0 — Timeout Enable n (n = 96 to 127)
0x7AD8 FWEID80 — Error Interrupt Disable Register 80
  [31:0] TOD31 to TOD0 — Timeout Disable n (n = 96 to 127)
0x7AE0 FWEIS81 — Error Interrupt Status Register 81
  [31:0] TOS31 to TOS0 — Timeout Status Flag n (n = 64 to 95)
0x7AE4 FWEIE81 — Error Interrupt Enable Register 81
  [31:0] TOE31 to TOE0 — Timeout Enable n (n = 64 to 95)
0x7AE8 FWEID81 — Error Interrupt Disable Register 81
  [31:0] TOD31 to TOD0 — Timeout Disable n (n = 64 to 95)
0x7AF0 FWEIS82 — Error Interrupt Status Register 82
  [31:0] TOS31 to TOS0 — Timeout Status Flag n (n = 32 to 63)
0x7AF4 FWEIE82 — Error Interrupt Enable Register 82
  [31:0] TOE31 to TOE0 — Timeout Enable n (n = 32 to 63)
0x7AF8 FWEID82 — Error Interrupt Disable Register 82
  [31:0] TOD31 to TOD0 — Timeout Disable n (n = 32 to 63)
0x7B00 FWEIS83 — Error Interrupt Status Register 83
  [31:0] TOS31 to TOS0 — Timeout Status Flag n (n = 0 to 31)
0x7B04 FWEIE83 — Error Interrupt Enable Register 83
  [31:0] TOE31 to TOE0 — Timeout Enable n (n = 0 to 31)
0x7B08 FWEID83 — Error Interrupt Disable Register 83
  [31:0] TOD31 to TOD0 — Timeout Disable n (n = 0 to 31)
0x7C00 FWMIS0 — Monitoring Interrupt Status Register 0
  [17] MACADAS — MAC Address Deleted Aging Status Flag
  [3] VLANTFS — VLAN Table Full Status Flag
  [2] MACTFS — MAC Table Full Status Flag
  [0] LTHTFS — L3 Table Full Status Flag
0x7C04 FWMIE0 — Monitoring Interrupt Enable Register 0
  [all] fields
    0=Interrupt disabled; 1=Interrupt Enabled
  [17] MACADAE — MAC Address Deleted Aging Enable
  [3] VLANTFE — VLAN Table Full Enable
  [2] MACTFE — MAC Table Full Enable
  [0] LTHTFE — L3 Table Full Enable
0x7C08 FWMID0 — Monitoring Interrupt Disable Register 0
  [17] MACADAD — MAC Address Deleted Aging Disable
  [3] VLANTFD — VLAN Table Full Disable
  [2] MACTFD — MAC Table Full Disable
  [0] LTHTFD — L3 Table Full Disable
